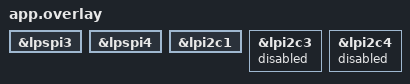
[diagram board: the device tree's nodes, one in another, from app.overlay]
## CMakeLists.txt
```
# SPDX-License-Identifier: Apache-2.0

cmake_minimum_required(VERSION 3.20.0)
set(BOARD teensy41)
find_package(Zephyr REQUIRED HINTS $ENV{ZEPHYR_BASE})
project(app)

target_sources(app PRIVATE src/main.cpp src/base_teensy_intranet.cpp)

add_subdirectory(ARCH)
include_directories(ARCH/include)
include_directories(include)
target_link_libraries(app PRIVATE 2024_I_AV_SW_TEENSY)


# The external static library that we are linking with does not know
# how to build for this platform so we export all the flags used in
# this zephyr build to the external build system.
#
# Other external build systems may be self-contained enough that they
# do not need any build information from zephyr. Or they may be
# incompatible with certain zephyr options and need them to be
# filtered out.

zephyr_get_include_directories_for_lang_as_string(       C includes)
zephyr_get_system_include_directories_for_lang_as_string(C system_includes)
zephyr_get_compile_definitions_for_lang_as_string(       C definitions)
zephyr_get_compile_options_for_lang_as_string(           C options)

set(external_project_cflags
  "${includes} ${definitions} ${options} ${system_includes}"
  )

include(ExternalProject)

# Add an external project to be able download and build the third
# party library. In this case downloading is not necessary as it has
# been committed to the repository.
# set(mylib_src_dir   ${CMAKE_CURRENT_SOURCE_DIR}/mylib)
# set(mylib_build_dir ${CMAKE_CURRENT_BINARY_DIR}/mylib)

# set(MYLIB_LIB_DIR     ${mylib_build_dir}/lib)
# set(MYLIB_INCLUDE_DIR ${mylib_src_dir}/include)

if(CMAKE_GENERATOR STREQUAL "Unix Makefiles")
# https://www.gnu.org/software/make/manual/html_node/MAKE-Variable.html
set(submake "$(MAKE)")
else() # Obviously no MAKEFLAGS. Let's hope a "make" can be found somewhere.
set(submake "make")
endif()

# ExternalProject_Add(
#   mylib_project                 # Name for custom target
#   PREFIX     ${mylib_build_dir} # Root dir for entire project
#   SOURCE_DIR ${mylib_src_dir}
#   BINARY_DIR ${mylib_src_dir} # This particular build system is invoked from the root
#   CONFIGURE_COMMAND ""    # Skip configuring the project, e.g. with autoconf
#   BUILD_COMMAND
#   ${submake}
#   PREFIX=${mylib_build_dir}
#   CC=${CMAKE_C_COMPILER}
#   AR=${CMAKE_AR}
#   CFLAGS=${external_project_cflags}
#   INSTALL_COMMAND ""      # This particular build system has no install command
#   BUILD_BYPRODUCTS ${MYLIB_LIB_DIR}/libmylib.a
#   )
# 
# Create a wrapper CMake library that our app can link with
# add_library(mylib_lib STATIC IMPORTED GLOBAL)
# add_dependencies(
#   mylib_lib
#   mylib_project
#   )
# set_target_properties(mylib_lib PROPERTIES IMPORTED_LOCATION             ${MYLIB_LIB_DIR}/libmylib.a)
# set_target_properties(mylib_lib PROPERTIES INTERFACE_INCLUDE_DIRECTORIES ${MYLIB_INCLUDE_DIR})
# 
# target_link_libraries(app PUBLIC mylib_lib)
```

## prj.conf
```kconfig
# stole the config from https://github.com/borrelunde/zephyr-cpp-synchronization-app-sample/tree/master/application
# Global switch, turns on/off the logging.
CONFIG_LOG=y

# Enables coloring of errors (red) and warnings (yellow).
CONFIG_LOG_BACKEND_SHOW_COLOR=n

# Default level, sets the logging level used by modules that are not setting
# their own logging level.
# The log levels are: 0 off, 1 error, 2 warning, 3 info, 4 debug
CONFIG_LOG_DEFAULT_LEVEL=3

# Deferred mode.
CONFIG_LOG_MODE_DEFERRED=y

# Immediate (synchronous) mode.
CONFIG_LOG_MODE_IMMEDIATE=n

# Minimal footprint mode.
CONFIG_LOG_MODE_MINIMAL=n

# C++
CONFIG_CPP=y
CONFIG_CPP_MAIN=y
CONFIG_CPP_EXCEPTIONS=y
CONFIG_GLIBCXX_LIBCPP=y

# SPI
CONFIG_SPI=y
#these are active because I saw these in a repo
CONFIG_SPI_MCUX_LPSPI_DMA=y
CONFIG_SPI_MCUX_FLEXCOMM_DMA=y

# this is active because it enables async calls
CONFIG_POLL=y
CONFIG_SPI_ASYNC=y
```

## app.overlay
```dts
// spi 3; 39 26 27 38 MISO MOSI SCK CS
&lpspi3 {
    status = "okay";
};

// spi 4; 10 11 12 13 CS MOSI MISO SCK
&lpspi4 {
    status = "okay";
};

/*SCL/SDA 19/18*/
&lpi2c1 {
    status = "okay";
};

/* SCL/SDA 16/17 */
&lpi2c3 {
    status = "disabled";
};

/* SCL/SDA 24/25*/
&lpi2c4 {
    status = "disabled";
};
```

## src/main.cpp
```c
#include "base_teensy_intranet.hpp"


int main(){
    BaseTeensyIntranetSPI spi_device;
    uint8_t array[3] = {1, 2, 3};
    uint8_t byte = 7;

    while(1){
        spi_device.appendToSend(array, 3);
        spi_device.flush();
    }
}
```

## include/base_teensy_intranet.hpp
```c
//
// Created by owhenthesaints on 13/04/24.
//

#ifndef APP_BASETEENSYINTRANET_H
#define APP_BASETEENSYINTRANET_H

#include <zephyr/drivers/spi.h>
#include <vector>

// just to avoid magic constants
#define BUFFER_LENGTH 1

class BaseTeensyIntranet {
public:
    explicit BaseTeensyIntranet(const device *device);

    BaseTeensyIntranet(BaseTeensyIntranet &) = delete;

    BaseTeensyIntranet& operator=(const BaseTeensyIntranet &) = delete;

    virtual bool getWriteSuccessful() const;

    virtual void appendToSend(uint8_t *bufffer, size_t size);

    virtual void appendToSend(uint8_t &buffer);

    virtual bool flush();

protected:

    const struct device *dev;

    virtual uint8_t writeByte(const uint8_t &byte) = 0;


    uint8_t writeError;
private:
    std::vector<uint8_t> classBuffer;


};

class BaseTeensyIntranetSPI : public BaseTeensyIntranet {
public:
    explicit BaseTeensyIntranetSPI(const device *device = device_get_binding(DEVICE_DT_NAME(DT_NODELABEL(lpspi4))));

    // know if you managed to write
    bool getWriteSuccessful() const override;

    bool getReadSuccessful() const;

private:
    uint8_t byteBufferRx[BUFFER_LENGTH] = {0};
    uint8_t byteBufferTx[BUFFER_LENGTH] = {0};
    //Synchronous read buffer
    const struct spi_buf rxBufferSync;
    //Synchronous write buffer
    const struct spi_buf txBufferSync;
    uint8_t readError;
    uint8_t writeError;
    const struct spi_config spiCfg;
    // synchronous transmition set points to an array of buffers
    const struct spi_buf_set txBuffersSync;
    // synchronous recieve set
    const struct spi_buf_set rxBuffersSync;

    //functions to read write internally
    uint8_t readByte(uint8_t &byte);

    uint8_t writeByte(const uint8_t &byte) override;

};

/**
 * @brief a class to implement I2C communication
 */
class BaseTeensyIntranetI2C : public BaseTeensyIntranet {
public:
    explicit BaseTeensyIntranetI2C(const device *i2c_dev = device_get_binding(DEVICE_DT_NAME(DT_NODELABEL(lpi2c1))),
                                   const uint8_t &slave_adress = 0x06);

private:
    uint32_t i2cCfg;
    uint8_t i2c_data[BUFFER_LENGTH]{};
    uint8_t i2c_slave_address;
    uint8_t writeByte(const uint8_t &byte) override;

};

#endif //APP_BASETEENSYINTRANET_H
```

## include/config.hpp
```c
#ifndef INC_2024_I_AV_TEENSY_CONFIG_HPP
#define INC_2024_I_AV_TEENSY_CONFIG_HPP

#define CALIBRATION_DURATION_MS 0
#define ASCENT_DURATION_MS 1
#define HOVERING_DURATION_MS 0
#define DESCENT_DURATION_MS 0

#endif /*INC_2024_I_AV_TEENSY_CONFIG_HPP*/
```

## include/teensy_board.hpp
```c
#ifndef INC_2024_I_AV_TEENSY_TEENSY_BOARD_HPP
#define INC_2024_I_AV_TEENSY_TEENSY_BOARD_HPP

#include "config.hpp"
#include "system/system.hpp"
#include "telemetry/teensy_telemetry.hpp"
#include "sensors/teensy_sensors.hpp"

class TeensyBoard {
private:
    SystemClass sys = SystemClass();
    TeensyTelemetry tele = TeensyTelemetry();
    TeensySensors sens = TeensySensors();

    FSMState stateInit();
    FSMState stateCalibration();
    FSMState stateArmed();
    FSMState statePressurize();
    FSMState stateFlightReady();
    FSMState stateIgnite();
    FSMState stateIgnition();
    FSMState stateAscent();
    FSMState stateHovering();
    FSMState stateDescent();
    FSMState stateTouchdown();
    FSMState stateAbort();

    bool armedReady();
    bool pressurizeReady();
    bool flightReadyReady();
    bool igniteReady();
    bool ignitionReady();
    bool ignitionFinishedSuccessfully();

    bool shouldAbort();

public:
    explicit TeensyBoard() {}

    void loopOnce();

    time_millis_t getCurrentTimeMillis();
    void stateUpdate();    
    void acquire();
    void tick();
    void output();
};

#endif /*INC_2024_I_AV_TEENSY_TEENSY_BOARD_HPP*/
```

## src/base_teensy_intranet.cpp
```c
//
// Created by owhenthesaints on 14/04/24.
//
#include "base_teensy_intranet.hpp"
#include <zephyr/drivers/spi.h>
#include <zephyr/drivers/i2c.h>
#include <stdexcept>

#define FREQUENCY 1000000
#define CHIP_SELECT_OPT 0
#define TEST_BUFFER_LENGTH 1000
// define the number
#define SLAVE_NUMBER 0
#define NUM_READ_BUFFERS


// possibilité de définir le channel sur lequel on veut le spi BaseTeensyIntranet(device_get_binding(DEVICE_DT_NAME(DT_NODELABEL(lpspi4))))
// spi 4; 10 11 12 13 CS MOSI MISO SCK
// spi 3; 39 26 27 38 MISO MOSI SCK CS
BaseTeensyIntranetSPI::BaseTeensyIntranetSPI(const device *device) : BaseTeensyIntranet(device),
                                                                     rxBufferSync{byteBufferRx, BUFFER_LENGTH},
                                                                     txBufferSync{byteBufferTx, BUFFER_LENGTH},
                                                                     readError(0),
                                                                     writeError(0),
                                                                     spiCfg{FREQUENCY,
                                                                              SPI_OP_MODE_MASTER | SPI_TRANSFER_MSB |
                                                                              SPI_WORD_SET(8) |
                                                                              SPI_MODE_CPHA, SLAVE_NUMBER,
                                                                              CHIP_SELECT_OPT},
                                                                     txBuffersSync{&txBufferSync, 1},
                                                                     rxBuffersSync{&rxBufferSync, 1} {}

uint8_t BaseTeensyIntranetSPI::readByte(uint8_t &byte) {
    readError = spi_read(dev, &spiCfg, &rxBuffersSync);
    return byteBufferRx[0];
}

uint8_t BaseTeensyIntranetSPI::writeByte(const uint8_t &byte) {
    byteBufferTx[0] = byte;
    writeError = spi_transceive(dev, &spiCfg, &txBuffersSync, &rxBuffersSync);
    return byteBufferRx[0];
}

bool BaseTeensyIntranetSPI::getWriteSuccessful() const {
    return !writeError;
}

bool BaseTeensyIntranetSPI::getReadSuccessful() const {
    return !readError;
}

void BaseTeensyIntranet::appendToSend(uint8_t &val) {
    classBuffer.push_back(val);
}

void BaseTeensyIntranet::appendToSend(uint8_t *vals, size_t size) {
    classBuffer.reserve(size);
    copy(vals, vals + size, std::back_inserter(classBuffer));
}

// l'implémentation n'est pas très efficace mieux de faire un circular buffer
bool BaseTeensyIntranet::flush() {
    while (!classBuffer.empty()) {
        writeByte(classBuffer.front());
        if (writeError)
            return false;
        classBuffer.erase(classBuffer.begin());
    }
    return true;
}

BaseTeensyIntranet::BaseTeensyIntranet(const device *const device) : dev(device), writeError(0) {}

BaseTeensyIntranetI2C::BaseTeensyIntranetI2C(const device *const i2c_dev, const uint8_t & slave_addr) : BaseTeensyIntranet(i2c_dev),
                                                                            i2cCfg(I2C_SPEED_SET(I2C_SPEED_STANDARD) |
                                                                                   I2C_MODE_CONTROLLER),
                                                                            i2c_slave_address(slave_addr) {
    if (!device_is_ready(dev))
        throw std::runtime_error("bad i2c init");
    if (i2c_configure(dev, i2cCfg))
        throw std::runtime_error("bad config i2c");


}

/**
 * @brief a function that writes a byte in I2C
 * @param byte the byte to write
 * @return writeError
 */
uint8_t BaseTeensyIntranetI2C::writeByte(const uint8_t &byte) {
    i2c_data[0] = byte;
    writeError = i2c_write(dev, i2c_data, BUFFER_LENGTH, i2c_slave_address);
    return writeError;
}

bool BaseTeensyIntranet::getWriteSuccessful() const {
    return !writeError;
}
```

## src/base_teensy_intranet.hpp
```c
//
// Created by owhenthesaints on 13/04/24.
//

#ifndef APP_BASETEENSYINTRANET_H
#define APP_BASETEENSYINTRANET_H

#include <zephyr/drivers/spi.h>
#include <common/channel/base_intranet_channel.hpp>
// just to avoid magic constants
#define BUFFER_LENGTH 1

class BaseTeensyIntranet : public virtual BaseIntranetChannel {
public:
    BaseTeensyIntranet();

    virtual void init() = 0;

    bool readByte(uint8_t &byte) override;
    bool writeByte(const uint8_t &byte) override;

protected:
    uint8_t byteBufferRx[BUFFER_LENGTH] = {0};
    uint8_t byteBufferTx[BUFFER_LENGTH] = {0};
    //Synchronous read buffer
    const struct spi_buf  rxBufferSync;
    //Synchronous write buffer
    const struct spi_buf txBufferSync;
private:
    const struct device * dev;
    const struct spi_config spiCfg;
    // synchronous transmition set points to an array of buffers
    const struct spi_buf_set txBuffersSync;
    // synchronous recieve set
    const struct spi_buf_set rxBuffersSync;
};


#endif //APP_BASETEENSYINTRANET_H
```

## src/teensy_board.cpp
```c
#include "teensy_board.hpp"

void TeensyBoard::stateUpdate() {
	FSMState current = sys.get().state;
	FSMState next = ABORT_STATE;

    switch (current) {
        case INIT_STATE:
			next = stateInit();
		case CALIBRATION_STATE:
			next = stateCalibration();
		case ARMED_STATE:
			next = stateArmed();
		case PRESSURIZE_STATE:
			next = statePressurize();
		case FLIGHTREADY_STATE:
			next = stateFlightReady();
		case IGNITE_STATE:
			next = stateIgnite();
		case IGNITION_STATE:
			next = stateIgnition();
		case ASCENT_STATE:
			next = stateAscent();
		case HOVERING_STATE:
			next = stateHovering();
		case DESCENT_STATE:
			next = stateDescent();
		case TOUCHDOWN_STATE:
			next = stateTouchdown();
		case ABORT_STATE:
			next = stateAbort();
	}

	sys.setState(next);

    if (current != next) {
		sys.setLastFsmTransition(sys.get().time);
	}

    // TODO DMA to rpi
}

void TeensyBoard::acquire() {

}

void TeensyBoard::tick() {

}

void TeensyBoard::output() {
    
}

FSMState TeensyBoard::stateInit() {
    TelemetryStatus teleStatus = tele.get();

    if(teleStatus.commandId == CMD_AV_STATE) {
        FSMState nextState = (FSMState) teleStatus.commandValue;
        tele.resetCommand();

        switch(nextState) {
            case CALIBRATION_STATE:
                sens.setCalibrated(false);
                return CALIBRATION_STATE;

            case ARMED_STATE:
                if(!armedReady()) break;
                return ARMED_STATE;
            default:
                break;
        }
    }

    return INIT_STATE;
}

FSMState TeensyBoard::stateCalibration() {
    TelemetryStatus teleStatus = tele.get();
    SystemStatus sysStatus = sys.get();

    time_millis_t calibratingSince = sysStatus.time - sysStatus.lastFSMTransition;

    // If calibration is finished, return to INIT
    if(calibratingSince >= CALIBRATION_DURATION_MS) {
        sens.setCalibrated(true);
        return INIT_STATE;
    }
    
    return CALIBRATION_STATE;
}

FSMState TeensyBoard::stateArmed() {
    if(shouldAbort())
        return ABORT_STATE;
           
    TelemetryStatus teleStatus = tele.get();

    if(teleStatus.commandId == CMD_AV_STATE) {
        FSMState nextState = (FSMState) teleStatus.commandValue;
        tele.resetCommand();

        switch(nextState) {
            case INIT_STATE:
                return INIT_STATE;
            case ABORT_STATE:
                return ABORT_STATE;
            case PRESSURIZE_STATE:
                if(!pressurizeReady()) break;
                return PRESSURIZE_STATE;
            default:
                break;
        }
    }

    return ARMED_STATE;

}

FSMState TeensyBoard::statePressurize() {
    if(shouldAbort())
        return ABORT_STATE;
        
    TelemetryStatus teleStatus = tele.get();

    if(teleStatus.commandId == CMD_AV_STATE) {
        FSMState nextState = (FSMState) teleStatus.commandValue;
        tele.resetCommand();

        switch(nextState) {
            case ABORT_STATE:
                return ABORT_STATE;
            case FLIGHTREADY_STATE:
                flightReadyReady();
                return FLIGHTREADY_STATE;
            default:
                break;
        }
    }

    return PRESSURIZE_STATE;
}

FSMState TeensyBoard::stateFlightReady() {
    if(shouldAbort())
        return ABORT_STATE;

    TelemetryStatus teleStatus = tele.get();

    if(teleStatus.commandId == CMD_AV_STATE) {
        FSMState nextState = (FSMState) teleStatus.commandValue;
        tele.resetCommand();

        switch(nextState) {
            case ABORT_STATE:
                return ABORT_STATE;
            case IGNITE_STATE:
                if(!igniteReady()) break;
                return IGNITE_STATE;
            default:
                break;
        }
    }

    return FLIGHTREADY_STATE;
}


FSMState TeensyBoard::stateIgnite() {
    if(shouldAbort())
        return ABORT_STATE;
           
    TelemetryStatus teleStatus = tele.get();
    SystemStatus sysStatus = sys.get();

    if(teleStatus.commandId == CMD_AV_STATE) {
        FSMState nextState = (FSMState) teleStatus.commandValue;
        tele.resetCommand();

        switch(nextState) {
            case ABORT_STATE:
                return ABORT_STATE;
            default:
                break;
        }
    }

    if(ignitionReady())
        return IGNITION_STATE;

    return IGNITE_STATE;
}

FSMState TeensyBoard::stateIgnition() {
    if(shouldAbort())
        return ABORT_STATE;
           
    TelemetryStatus teleStatus = tele.get();
    SystemStatus sysStatus = sys.get();

    if(teleStatus.commandId == CMD_AV_STATE) {
        FSMState nextState = (FSMState) teleStatus.commandValue;
        tele.resetCommand();

        switch(nextState) {
            case ABORT_STATE:
                return ABORT_STATE;
            default:
                break;
        }
    }

    if(ignitionFinishedSuccessfully())
        return ASCENT_STATE;

    return IGNITION_STATE;
}

// TODO stateIgnition

FSMState TeensyBoard::stateAscent() {
    if(shouldAbort())
        return ABORT_STATE;
           
    TelemetryStatus teleStatus = tele.get();
    SystemStatus sysStatus = sys.get();

    if(teleStatus.commandId == CMD_AV_STATE) {
        FSMState nextState = (FSMState) teleStatus.commandValue;
        tele.resetCommand();

        switch(nextState) {
            case ABORT_STATE:
                return ABORT_STATE;
            default:
                break;
        }
    }

    if(sysStatus.time - sysStatus.lastFSMTransition >= ASCENT_DURATION_MS)
        return HOVERING_STATE;

    return ASCENT_STATE;
}

FSMState TeensyBoard::stateHovering() {
    if(shouldAbort())
        return ABORT_STATE;
    
    TelemetryStatus teleStatus = tele.get();
    SystemStatus sysStatus = sys.get();

    if(teleStatus.commandId == CMD_AV_STATE) {
        FSMState nextState = (FSMState) teleStatus.commandValue;
        tele.resetCommand();

        switch(nextState) {
            case ABORT_STATE:
                return ABORT_STATE;
            default:
                break;
        }
    }

    if(sysStatus.time - sysStatus.lastFSMTransition >= HOVERING_DURATION_MS)
        return DESCENT_STATE;

    return HOVERING_STATE;
}

FSMState TeensyBoard::stateDescent() {
    if(shouldAbort())
        return ABORT_STATE;
    
    TelemetryStatus teleStatus = tele.get();
    SystemStatus sysStatus = sys.get();

    if(teleStatus.commandId == CMD_AV_STATE) {
        FSMState nextState = (FSMState) teleStatus.commandValue;
        tele.resetCommand();

        switch(nextState) {
            case ABORT_STATE:
                return ABORT_STATE;
            default:
                break;
        }
    }

    if(sysStatus.time - sysStatus.lastFSMTransition >= DESCENT_DURATION_MS)
        return TOUCHDOWN_STATE;

    return DESCENT_STATE;
}

FSMState TeensyBoard::stateTouchdown() {
    if(shouldAbort())
        return ABORT_STATE;
    
    SystemStatus sysStatus = sys.get();

    return TOUCHDOWN_STATE;
}
```
